AUTOSAR XML (schema 4-0-3)
package /AUTOSAR_NvM/SwComponentTypes
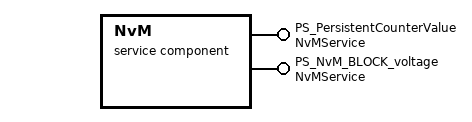
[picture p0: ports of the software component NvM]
  service sw component type NvM
    provide port PS_PersistentCounterValue: provided-interface=NvMService
    provide port PS_NvM_BLOCK_voltage: provided-interface=NvMService
    behavior NvMIntBeh: handle-termination-and-restart=NO-SUPPORT
      18 x operation invoked event:
        EV_GetErrorStatus_PersistentCounterValue: start-on-event=RE_GetErrorStatus, operation=PS_PersistentCounterValue.GetErrorStatus
        EV_SetDataIndex_PersistentCounterValue: start-on-event=RE_SetDataIndex, operation=PS_PersistentCounterValue.SetDataIndex
        EV_GetDataIndex_PersistentCounterValue: start-on-event=RE_GetDataIndex, operation=PS_PersistentCounterValue.GetDataIndex
        EV_SetRamBlockStatus_PersistentCounterValue: start-on-event=RE_SetRamBlockStatus, operation=PS_PersistentCounterValue.SetRamBlockStatus
        EV_ReadBlock_PersistentCounterValue: start-on-event=RE_ReadBlock, operation=PS_PersistentCounterValue.ReadBlock
        EV_WriteBlock_PersistentCounterValue: start-on-event=RE_WriteBlock, operation=PS_PersistentCounterValue.WriteBlock
        EV_RestoreBlockDefaults_PersistentCounterValue: start-on-event=RE_RestoreBlockDefaults, operation=PS_PersistentCounterValue.RestoreBlockDefaults
        EV_EraseBlock_PersistentCounterValue: start-on-event=RE_EraseBlock, operation=PS_PersistentCounterValue.EraseBlock
        EV_InvalidateNvBlock_PersistentCounterValue: start-on-event=RE_InvalidateNvBlock, operation=PS_PersistentCounterValue.InvalidateNvBlock
        EV_GetErrorStatus_NvM_BLOCK_voltage: start-on-event=RE_GetErrorStatus, operation=PS_NvM_BLOCK_voltage.GetErrorStatus
        EV_SetDataIndex_NvM_BLOCK_voltage: start-on-event=RE_SetDataIndex, operation=PS_NvM_BLOCK_voltage.SetDataIndex
        EV_GetDataIndex_NvM_BLOCK_voltage: start-on-event=RE_GetDataIndex, operation=PS_NvM_BLOCK_voltage.GetDataIndex
        EV_SetRamBlockStatus_NvM_BLOCK_voltage: start-on-event=RE_SetRamBlockStatus, operation=PS_NvM_BLOCK_voltage.SetRamBlockStatus
        EV_ReadBlock_NvM_BLOCK_voltage: start-on-event=RE_ReadBlock, operation=PS_NvM_BLOCK_voltage.ReadBlock
        EV_WriteBlock_NvM_BLOCK_voltage: start-on-event=RE_WriteBlock, operation=PS_NvM_BLOCK_voltage.WriteBlock
        EV_RestoreBlockDefaults_NvM_BLOCK_voltage: start-on-event=RE_RestoreBlockDefaults, operation=PS_NvM_BLOCK_voltage.RestoreBlockDefaults
        EV_EraseBlock_NvM_BLOCK_voltage: start-on-event=RE_EraseBlock, operation=PS_NvM_BLOCK_voltage.EraseBlock
        EV_InvalidateNvBlock_NvM_BLOCK_voltage: start-on-event=RE_InvalidateNvBlock, operation=PS_NvM_BLOCK_voltage.InvalidateNvBlock
      port-api-options:
        {enable-take-address=true, indirect-api=false, port-defined-argument-value{value=7, value-type=NvM_BlockIdType}, port=PS_PersistentCounterValue}
        {enable-take-address=true, indirect-api=false, port-defined-argument-value{value=9, value-type=NvM_BlockIdType}, port=PS_NvM_BLOCK_voltage}
      10 x runnable, all with can-be-invoked-concurrently=true:
        RE_MainFunction: symbol=NvM_MainFunction
        RE_GetErrorStatus: arguments=[symbol=BlockId, symbol=RequestResultPtr], symbol=NvM_Rte_GetErrorStatus
        RE_SetDataIndex: arguments=[symbol=BlockId, symbol=DataIndex], symbol=NvM_Rte_SetDataIndex
        RE_GetDataIndex: arguments=[symbol=BlockId, symbol=DataIndex], symbol=NvM_Rte_GetDataIndex
        RE_SetRamBlockStatus: arguments=[symbol=BlockId, symbol=BlockChanged], symbol=NvM_Rte_SetRamBlockStatus
        RE_ReadBlock: arguments=[symbol=BlockId, symbol=NvM_DstPtr], symbol=NvM_Rte_ReadBlock
        RE_WriteBlock: arguments=[symbol=BlockId, symbol=NvM_SrcPtr], symbol=NvM_Rte_WriteBlock
        RE_RestoreBlockDefaults: arguments=[symbol=BlockId, symbol=NvM_DestPtr], symbol=NvM_Rte_RestoreBlockDefaults
        RE_EraseBlock: runnable-entity-argument=symbol=BlockId, symbol=NvM_Rte_EraseNvBlock
        RE_InvalidateNvBlock: runnable-entity-argument=symbol=BlockId, symbol=NvM_Rte_InvalidateNvBlock
package /EB_NvM/SwcImplementations
  swc implementation NvMImpl: programming-language=C, sw-version=1.0.0, vendor-id=1, behavior=NvMIntBeh
    code-descriptors:
      code Code: artifact-descriptors=autosar-engineering-object={short-label=EngObject, category=SWSRC}
    resource consumption Resources
      memory section CODE: sw-addrmethod=CODE
